VERSION ""

NS_ :

BS_:

BU_:

BO_ 3221225472 VECTOR__INDEPENDENT_SIG_MSG: 0 Vector__XXX
 SG_ FR_FlowRate : 0|8@1+ (1,0) [0|0] "" Vector__XXX
 SG_ FR_BellCrank : 8|8@1+ (1,0) [0|0] "" Vector__XXX

BO_ 880 HEARTBEAT: 2 Vector__XXX
 SG_ State : 0|8@1+ (1,0) [0|0] "" Vector__XXX
 SG_ Counter : 8|8@1+ (1,0) [0|0] "" Vector__XXX

BO_ 881 ERROR: 8 Vector__XXX
 SG_ Low_FlowRate : 0|8@1+ (1,0) [0|0] "" Vector__XXX

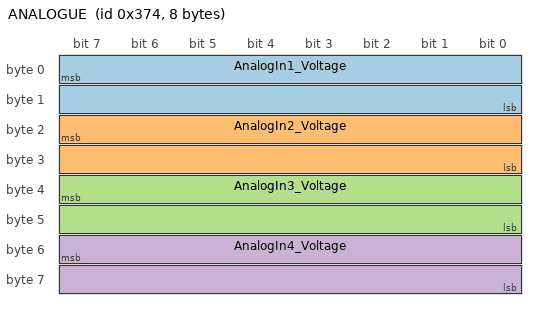
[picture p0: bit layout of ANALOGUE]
BO_ 884 ANALOGUE: 8 Vector__XXX
 SG_ AnalogIn1_Voltage : 7|16@0+ (0.001,0) [0|0] "V" Vector__XXX
 SG_ AnalogIn2_Voltage : 23|16@0+ (0.001,0) [0|0] "V" Vector__XXX
 SG_ AnalogIn3_Voltage : 39|16@0+ (0.001,0) [0|0] "V" Vector__XXX
 SG_ AnalogIn4_Voltage : 55|16@0+ (0.001,0) [0|0] "V" Vector__XXX
